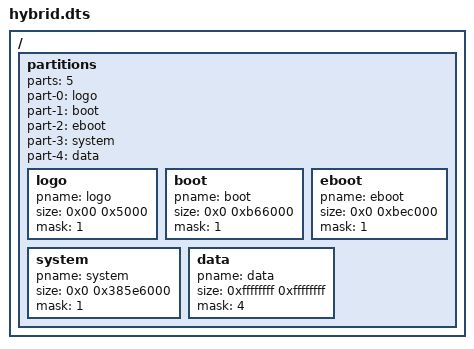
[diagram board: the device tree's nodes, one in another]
/*
 * Amlogic Ltd. GXBaby Plaform
 *
 */

/dts-v1/;

#include "gxbb_p200_1G_mibox3.dtsi"
/ {
	partitions: partitions{
		parts = <5>;
		part-0 = <&logo>;
		part-1 = <&boot>;
		part-2 = <&eboot>;
		part-3 = <&system>;
		part-4 = <&data>;
		logo:logo { // HybridELEC logo
			pname = "logo";
			size = <0x00 0x5000>;
			mask = <1>;
		};
		boot:boot{	// CoreELEC kernel
			pname = "boot";
			size = <0x0 0xb66000>;
			mask = <1>;
		};
		eboot:eboot{	// EmuELEC kernel
			pname = "eboot";
			size = <0x0 0xbec000>;
			mask = <1>;
		};
		system:system{	// HybridELEC system
			pname = "system";
			size = <0x0 0x385e6000>;
			mask = <1>;
		};
		data:data
		{
			pname = "data";
			size = <0xffffffff 0xffffffff>;
			mask = <4>;
		};
	};
};
